VERSION ""

NS_ :

BS_:

BU_:

BO_ 2158739747 test: 8 Vector__XXX
	SG_ Speed : 0|16@1- (0.1,0) [0|140] "mph" Vector__XXX
	SG_ APPS : 16|16@1- (0.1,0) [0|100] "" Vector__XXX

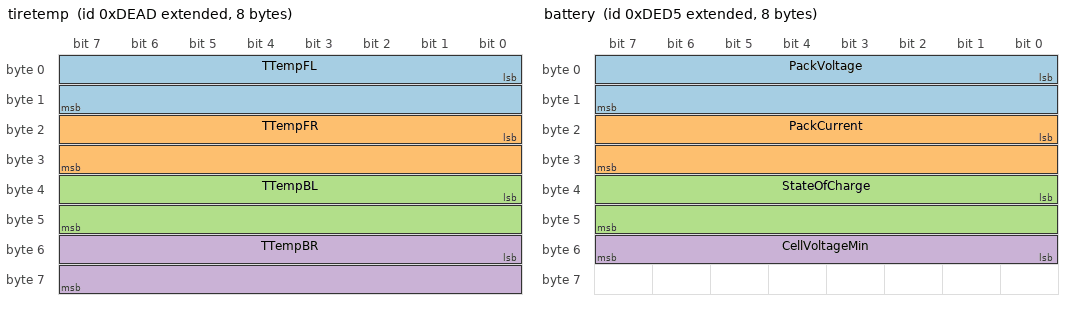
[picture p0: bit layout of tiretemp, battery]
BO_ 2147540653 tiretemp: 8 Vector__XXX
	SG_ TTempFL : 0|16@1- (0.1,0) [0|99] "C" Vector__XXX
	SG_ TTempFR : 16|16@1- (0.1,0) [0|99] "C" Vector__XXX
	SG_ TTempBL : 32|16@1- (0.1,0) [0|99] "C" Vector__XXX
	SG_ TTempBR : 48|16@1- (0.1,0) [0|99] "C" Vector__XXX

BO_ 2147540690 testagain: 8 Vector__XXX
	SG_ PackTemp : 0|16@1- (0.1, 0) [0|99] "C" Vector__XXX

BA_DEF_ SG_  "SPN" INT 0 524287;
BA_DEF_ BO_  "VFrameFormat" ENUM  "StandardCAN","ExtendedCAN","reserved","J1939PG";
BA_DEF_  "DatabaseVersion" STRING ;
BA_DEF_  "BusType" STRING ;
BA_DEF_  "ProtocolType" STRING ;
BA_DEF_  "DatabaseCompiler" STRING ;
BA_DEF_DEF_  "SPN" 0;
BA_DEF_DEF_  "VFrameFormat" "J1939PG";
BA_DEF_DEF_  "DatabaseVersion" "DEMO PLUS";
BA_DEF_DEF_  "BusType" "";
BA_DEF_DEF_  "ProtocolType" "";
BA_DEF_DEF_  "DatabaseCompiler" "";
BA_ "ProtocolType" "J1939";
BA_ "BusType" "CAN";
BA_ "DatabaseCompiler" "CSS ELECTRONICS (WWW.CSSELECTRONICS.COM)";
BA_ "DatabaseVersion" "1.0.0";
BA_ "SPN" SG_ 2158739747 WheelBasedVehicleSpeed 84;

BO_ 2147540691 braking: 8 Vector__XXX
    SG_ BrakePressure : 0|16@1- (0.1,0) [0|100] "%" Vector__XXX

BO_ 2147540692 motor: 8 Vector__XXX
    SG_ MotorRPM : 0|16@1- (1,0) [0|6000] "rpm" Vector__XXX

BO_ 2147540693 battery: 8 Vector__XXX
    SG_ PackVoltage : 0|16@1- (0.1,0) [0|420] "V" Vector__XXX
    SG_ PackCurrent : 16|16@1- (0.1,0) [0|300] "A" Vector__XXX
    SG_ StateOfCharge : 32|16@1- (0.1,0) [0|100] "%" Vector__XXX
    SG_ CellVoltageMin : 48|8@1- (0.01,0) [3|4.2] "V" Vector__XXX

BO_ 2147540694 gforce: 8 Vector__XXX
	SG_ LateralG : 0|16@1- (0.1,0) [-2|2] "G" Vector__XXX
	SG_ LongitudinalG : 16|16@1- (0.1,0) [-2|2] "G" Vector__XXX
